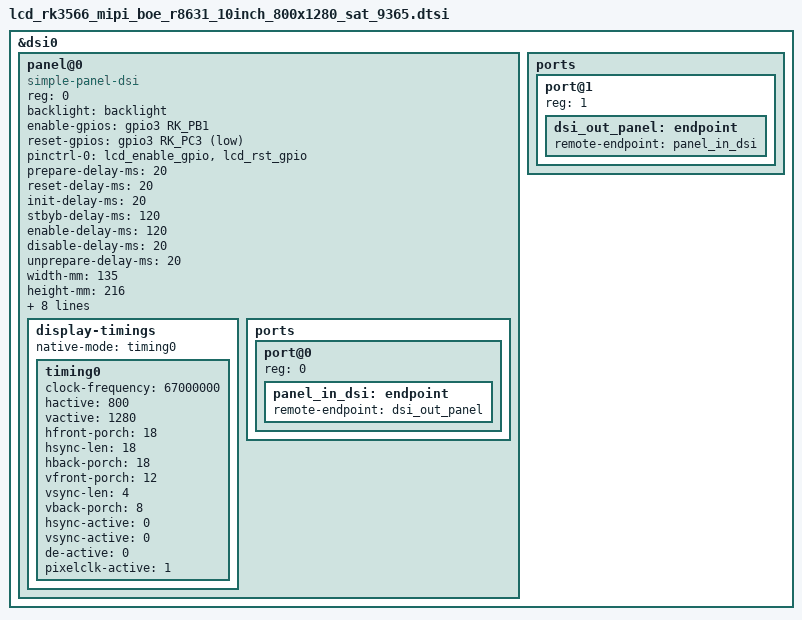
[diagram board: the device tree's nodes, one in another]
/*
* incar mipi lcd
*/
&dsi0 {
	status = "okay";
	//rockchip,lane-rate = <1000>;
	panel@0 {
		compatible = "simple-panel-dsi";
		reg = <0>;
		backlight = <&backlight>;
		//power-supply=<&vcc_3v3>;
		enable-gpios = <&gpio3 RK_PB1 GPIO_ACTIVE_HIGH>;
		//stbyb-gpios = <&gpio0 RK_PC0 GPIO_ACTIVE_LOW>;
		reset-gpios = <&gpio3 RK_PC3 GPIO_ACTIVE_LOW>;
		pinctrl-names = "default";
		pinctrl-0 = <&lcd_enable_gpio>, <&lcd_rst_gpio>;

		prepare-delay-ms = <20>;
		reset-delay-ms = <20>;
		init-delay-ms = <20>;
		stbyb-delay-ms = <120>;
		enable-delay-ms = <120>;
		disable-delay-ms = <20>;
		unprepare-delay-ms = <20>;

		width-mm = <135>;
		height-mm = <216>;

		dsi,flags = <(MIPI_DSI_MODE_VIDEO | MIPI_DSI_MODE_VIDEO_BURST |
			      MIPI_DSI_MODE_LPM | MIPI_DSI_MODE_EOT_PACKET)>;
		dsi,format = <MIPI_DSI_FMT_RGB888>;
		dsi,lanes = <4>;

		panel-init-sequence = [

15 00 02 E0 00 
15 00 02 E1 93 
15 00 02 E2 65 
15 00 02 E3 F8 
15 00 02 80 03 
15 00 02 E0 01 
15 00 02 00 00 
15 00 02 01 26 
15 00 02 17 00 
15 00 02 18 D7 //4.8V
15 00 02 19 01 //0.3V
15 00 02 1A 00 
15 00 02 1B D7   //VGMN=0
15 00 02 1C 01 
15 00 02 1F 70 	//VGH_REG=16.2V
15 00 02 20 2D 	//VGL_REG=-12V
15 00 02 21 2D 	//VGL_REG2=-12V
15 00 02 22 7E 
15 00 02 24 FD 
15 00 02 37 19 	//SS=1,BGR=1
15 00 02 35 28 	//SAP
15 00 02 38 05 	//JDT=101 zigzag inversion
15 00 02 39 08 
15 00 02 3A 12 
15 00 02 3C 7E 	//SET EQ3 for TE_H
15 00 02 3D FF 	//SET CHGEN_ON, modify 20140806
15 00 02 3E FF 	//SET CHGEN_OFF, modify 20140806
15 00 02 3F 7F 	//SET CHGEN_OFF2, modify 20140806
15 00 02 40 06 	//RSO=
15 00 02 41 A0 	//LN=640->1280 line
15 00 02 43 1E 	//VFP=
15 00 02 44 0B 	//VBP
15 00 02 55 02 	//DCDCM=1111
15 00 02 56 01 
15 00 02 57 6A 
15 00 02 58 09 
15 00 02 59 0A 	//VCL = -2.5V
15 00 02 5A 2E 	//VGH = 16.2V
15 00 02 5B 1A 	//VGL = -12V
15 00 02 5C 15 	//pump clk
15 00 02 5D 7F 
15 00 02 5E 5D 
15 00 02 5F 4B 
15 00 02 60 3E 
15 00 02 61 3A 
15 00 02 62 2B 
15 00 02 63 2F 
15 00 02 64 19 
15 00 02 65 32 
15 00 02 66 31 
15 00 02 67 31 
15 00 02 68 4F 
15 00 02 69 3E 
15 00 02 6A 47 
15 00 02 6B 36 
15 00 02 6C 31 
15 00 02 6D 24 
15 00 02 6E 12 
15 00 02 6F 02 
15 00 02 70 7F 
15 00 02 71 5D 
15 00 02 72 4B 
15 00 02 73 3E 
15 00 02 74 3A 
15 00 02 75 2B 
15 00 02 76 2F 
15 00 02 77 19 
15 00 02 78 32 
15 00 02 79 31 
15 00 02 7A 31 
15 00 02 7B 4F 
15 00 02 7C 3E 
15 00 02 7D 47 
15 00 02 7E 36 
15 00 02 7F 31 
15 00 02 80 24 
15 00 02 81 12 
15 00 02 82 02 
15 00 02 E0 02 
15 00 02 00 52 //RESET_EVEN
15 00 02 01 55 //VSSG_EVEN
15 00 02 02 55 //VSSG_EVEN
15 00 02 03 50 //STV2_ODD
15 00 02 04 77 //VDD2_ODD
15 00 02 05 57 //VDD1_ODD
15 00 02 06 55 //x
15 00 02 07 4E //CK11
15 00 02 08 4C //CK9
15 00 02 09 5F //x
15 00 02 0A 4A //CK7
15 00 02 0B 48 //CK5
15 00 02 0C 55 //x
15 00 02 0D 46 //CK3
15 00 02 0E 44 //CK1
15 00 02 0F 40 //STV1_ODD
15 00 02 10 55 //x
15 00 02 11 55 //x
15 00 02 12 55 //x
15 00 02 13 55 //x
15 00 02 14 55 //x
15 00 02 15 55 //x
15 00 02 16 53 //RESET__EVEN
15 00 02 17 55 //VSSG_EVEN
15 00 02 18 55 //VSSG_EVEN
15 00 02 19 51 //STV2_EVEN
15 00 02 1A 77 //VDD2_EVEN
15 00 02 1B 57 //VDD1_EVEN
15 00 02 1C 55 //x
15 00 02 1D 4F //CK12
15 00 02 1E 4D //CK10
15 00 02 1F 5F //x
15 00 02 20 4B //CK8
15 00 02 21 49 //CK6
15 00 02 22 55 //x
15 00 02 23 47 //CK4
15 00 02 24 45 //CK2
15 00 02 25 41 //STV1_EVEN
15 00 02 26 55 //x
15 00 02 27 55 //x
15 00 02 28 55 //x
15 00 02 29 55 //x
15 00 02 2A 55 //x
15 00 02 2B 55 //x
15 00 02 2C 13 //RESET_EVEN
15 00 02 2D 15 //VSSG_EVEN
15 00 02 2E 15 //VSSG_EVEN
15 00 02 2F 01 //STV2_ODD
15 00 02 30 37 //VDD2_ODD
15 00 02 31 17 //VDD1_ODD
15 00 02 32 15 //x
15 00 02 33 0D //CK11
15 00 02 34 0F //CK9
15 00 02 35 15 //x
15 00 02 36 05 //CK7
15 00 02 37 07 //CK5
15 00 02 38 15 //x
15 00 02 39 09 //CK3
15 00 02 3A 0B //CK1
15 00 02 3B 11 //STV1_ODD
15 00 02 3C 15 //x
15 00 02 3D 15 //x
15 00 02 3E 15 //x
15 00 02 3F 15 //x
15 00 02 40 15 //x
15 00 02 41 15 //x
15 00 02 42 12 //RESET__EVEN
15 00 02 43 15 //VSSG_EVEN
15 00 02 44 15 //VSSG_EVEN
15 00 02 45 00 //STV2_EVEN
15 00 02 46 37 //VDD2_EVEN
15 00 02 47 17 //VDD1_EVEN
15 00 02 48 15 //x
15 00 02 49 0C //CK12
15 00 02 4A 0E //CK10
15 00 02 4B 15 //x
15 00 02 4C 04 //CK8
15 00 02 4D 06 //CK6
15 00 02 4E 15 //x
15 00 02 4F 08 //CK4
15 00 02 50 0A //CK2
15 00 02 51 10 //STV1_EVEN
15 00 02 52 15 //x
15 00 02 53 15 //x
15 00 02 54 15 //x
15 00 02 55 15 //x
15 00 02 56 15 //x
15 00 02 57 15 //x
15 00 02 58 40 
15 00 02 5B 10 
15 00 02 5C 06 //STV_S0
15 00 02 5D 40 
15 00 02 5E 00 
15 00 02 5F 00 
15 00 02 60 40 //ETV_W
15 00 02 61 03 
15 00 02 62 04 
15 00 02 63 6C //CKV_ON
15 00 02 64 6C //CKV_OFF
15 00 02 65 75 
15 00 02 66 08 //ETV_S0
15 00 02 67 B4  //ckv_num/ckv_w
15 00 02 68 08  //CKV_S0
15 00 02 69 6C //CKV_ON
15 00 02 6A 6C //CKV_OFF
15 00 02 6B 0C  //dummy
15 00 02 6D 00 //GGND1
15 00 02 6E 00 //GGND2
15 00 02 6F 88 
15 00 02 75 BB //FLM_EN
15 00 02 76 00 
15 00 02 77 05 
15 00 02 78 2A //FLM_OFF
15 00 02 E0 04 
15 00 02 09 11 
15 00 02 0E 48 	//Source EQ option
15 00 02 2D 03 //defult 0x01
15 00 02 E0 00 
15 00 02 E6 02 //WD_Timer
15 00 02 E7 06 //WD_Timer 
15 00 02 35 00
05 78 01 11
05 64 01 29


			 
		];

		panel-exit-sequence = [
			05 01 01 28
			05 03 01 10
		];

		display-timings {
			native-mode = <&timing0>;
			timing0: timing0 {
				clock-frequency = <67000000>;
				hactive = <800>;
				vactive = <1280>;
				hfront-porch = <18>;
				hsync-len = <18>;
				hback-porch = <18>;
				vfront-porch = <12>;
				vsync-len = <4>;
				vback-porch = <8>;
				hsync-active = <0>;
				vsync-active = <0>;
				de-active = <0>;
				pixelclk-active = <1>;
			};
		};
		ports {
			#address-cells = <1>;
			#size-cells = <0>;

			port@0 {
				reg = <0>;
				panel_in_dsi: endpoint {
					remote-endpoint = <&dsi_out_panel>;
				};
			};
		};
	};

	ports {
		#address-cells = <1>;
		#size-cells = <0>;

		port@1 {
			reg = <1>;
			dsi_out_panel: endpoint {
				remote-endpoint = <&panel_in_dsi>;
			};
		};
	};
};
